# RE01_1500KB register map
Vendor: Renesas Electronics Corporation; Series: RE01_1500KB; File version: 1.20
CPU: CM0PLUS r0p1, little endian, MPU, no FPU, VTOR, 2 interrupt priority bits
Registers are 8-bit, read-write, reset 0x0 unless marked. A register's access mark holds for its fields unless they carry their own. Offsets are from the block's base; [hi:lo] are bit positions; {n}, {i} and the like mark numbered series; 'fields as' and 'values as' point back to an identical list; <NAME> marks a mode.

## SYSTEM — Energy Harvest Control Circuit
Base 0x4001E000
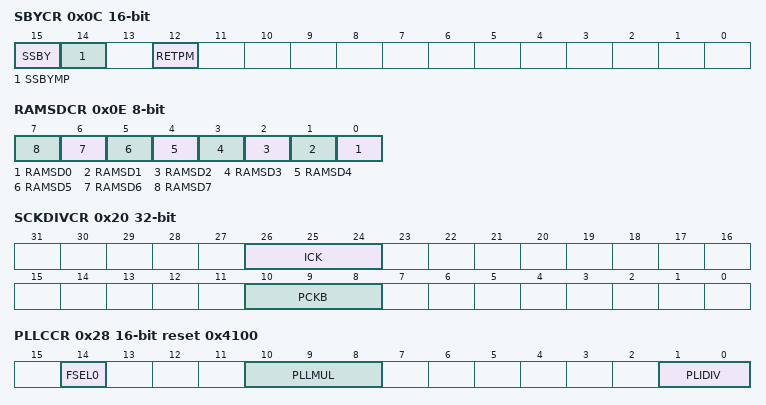
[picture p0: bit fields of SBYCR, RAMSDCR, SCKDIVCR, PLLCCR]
0x0C SBYCR 16-bit — Standby Control Register
  [15] SSBY — Software Standby
  [14] SSBYMP
  [12] RETPM
0x0E RAMSDCR
  [n] RAMSD{n} (n=0..7)
0x1C MSTPCRA 32-bit reset 0xFFBFFFFF — Module Stop Control Register A
  [22] MSTPA22 — Data Transfer Controller Module Stop
    0=Cancel the module-stop state; 1=Enter the module-stop state
0x20 SCKDIVCR 32-bit — System Clock Division Control Register
  [26:24] ICK — System Clock (ICLK)/Peripheral Module Clock A(PCLKA) Select
    0=/1; 1=/2; 2=/4; 3=/8; 4=/16; 5=/32; 6=/64; other=others (Setting prohibited)
  [10:8] PCKB — Peripheral Module Clock B (PCLKB) Select
    values as ICK
0x26 SCKSCR reset 0x1 — System Clock Source Control Register
  [2:0] CKSEL — Clock Source Select
    0=HOCO; 1=MOCO; 2=LOCO; 3=Main clock oscillator; 4=Sub-clock oscillator; 5=PLL; other=others (Setting prohibited)
0x28 PLLCCR 16-bit reset 0x4100 — PLL Clock Control Register
  [14] FSEL0
  [10:8] PLLMUL — PLL Frequency Multiplication Factor Select
    0=Setting prohibited; {v}=x{v+1} (v=1..7)
  [1:0] PLIDIV — PLL Input Frequency Division Ratio Select
    {v}=/{v+1} (v=0..3)
0x2A PLLCR reset 0x1 — PLL Control Register
  [0] PLLSTP — PLL Stop Control
    0=Operate the PLL; 1=Stop the PLL
0x32 MOSCCR reset 0x1 — Main Clock Oscillator Control Register
  [0] MOSTP — Main Clock Oscillator Stop
    0=Main clock oscillator is operating; 1=Main clock oscillator is stopped
0x36 HOCOCR (reset mask 0xFE) — High-Speed On-Chip Oscillator Control Register
  [0] HCSTP — HOCO Stop
    0=HOCO is operating; 1=HOCO is stopped
0x37 HOCOMCR (reset mask 0xFE) — High-Speed On-Chip Oscillator Mode Control Register
  [1:0] HCFRQ — HOCO Frequency Select
    0=24MHz; 1=32MHz; 2=48MHz; 3=64MHz
0x38 MOCOCR — Middle-Speed On-Chip Oscillator Control Register
  [0] MCSTP — MOCO Stop
    0=MOCO is operating; 1=MOCO is stopped
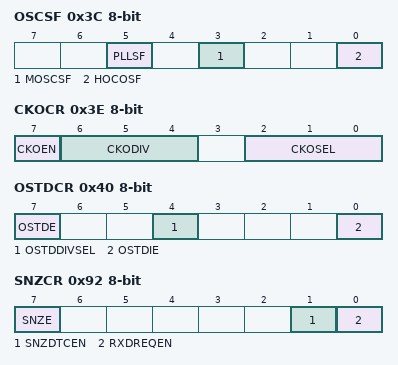
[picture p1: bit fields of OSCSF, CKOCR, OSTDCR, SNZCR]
0x3C OSCSF (reset mask 0xFE) — Oscillation Stabilization Flag Register
  [5] PLLSF ro — PLL Clock Oscillation Stabilization Flag
    0=The PLL clock is stopped or oscillation of the PLL clock has not yet become stable; 1=Oscillation of the PLL clock is stable so the clock is available for use as the system clock
  [3] MOSCSF ro — Main Clock Oscillation Stabilization Flag
    0=MOSTP = 1 (stopping the main clock oscillator) or oscillation of the main clock has not yet become stable; 1=Oscillation of the main clock is stable so the clock is available for use as the system clock
  [0] HOCOSF ro — HOCO Clock Oscillation Stabilization Flag
    0=The HOCO clock is stopped or oscillation of the HOCO clock has not yet become stable; 1=Oscillation of the HOCO clock is stable so the clock is available for use as the system clock
0x3D CKO32CR — 32kHz Clock Out Control Register
  [7] CKO32EN — 32kHz Clock Out enable
    0=Disable 32kHz clock out; 1=Enable 32kHz clock out
0x3E CKOCR — Clock Out Control Register
  [7] CKOEN — Clock Out enable
    0=Disable clock out; 1=Enable clock out
  [6:4] CKODIV — Clock Out input frequency Division Select
    0=/1; 1=/2; 2=/4; 3=/8; 4=/16; 5=/32; 6=/64; 7=/128
  [2:0] CKOSEL — Clock Out Source Select
    0=HOCO; 1=MOCO; 2=LOCO; 3=MOSC; 4=SOSC; 5=CCC_2K
0x40 OSTDCR — Oscillation Stop Detection Control Register
  [7] OSTDE — Oscillation Stop Detection Function Enable
    0=Oscillation stop detection function is disabled; 1=Oscillation stop detection function is enabled
  [4] OSTDDIVSEL
  [0] OSTDIE — Oscillation Stop Detection Interrupt Enable
    0=The oscillation stop detection interrupt is disabled. Oscillation stop detection is not notified to the POEG; 1=The oscillation stop detection interrupt is enabled. Oscillation stop detection is notified to the POEG
0x41 OSTDSR — Oscillation Stop Detection Status Register
  [0] OSTDF — Oscillation Stop Detection Flag
    0=The main clock oscillation stop has not been detected; 1=The main clock oscillation stop has been detected
0x92 SNZCR — Snooze Control Register
  [7] SNZE — Snooze Mode Enable
    0=Disable Snooze Mode; 1=Enable Snooze Mode
  [1] SNZDTCEN — DTC Enable in Snooze Mode
    0=Disable DTC operation; 1=Enable DTC operation
  [0] RXDREQEN — RXD0 Snooze Request Enable NOTE: Do not set to 1 other than in asynchronous mode.
    0=Ignore RXD0 falling edge in Standby mode; 1=Accept RXD0 falling edge in Standby mode as a request to transit to Snooze mode
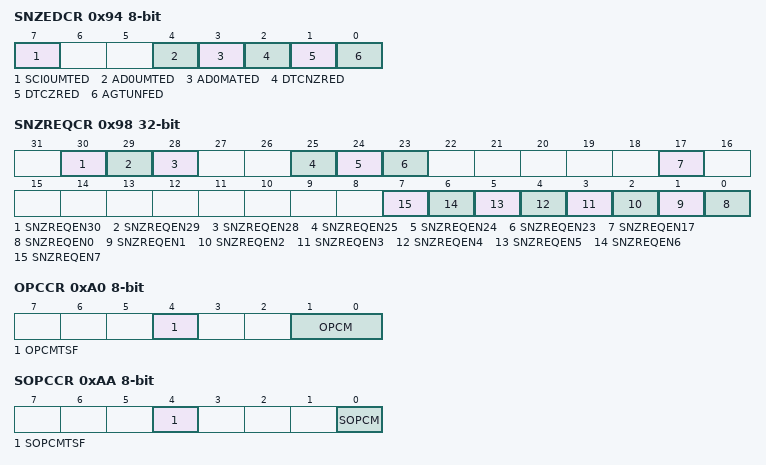
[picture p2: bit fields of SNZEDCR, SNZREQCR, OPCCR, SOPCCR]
0x94 SNZEDCR — Snooze End Control Register
  [all] fields
    0=Disable the Snooze End request; 1=Enable the Snooze End request
  [7] SCI0UMTED — SCI0 address unmatch Snooze End Enable
  [4] AD0UMTED — AD compare mismatch 0 Snooze End Enable
  [3] AD0MATED — AD compare match 0 Snooze End Enable
  [2] DTCNZRED — Not Last DTC transmission completion Snooze End Enable
  [1] DTCZRED — Last DTC transmission completion Snooze End Enable
  [0] AGTUNFED — AGT1 underflow Snooze End Enable
0x98 SNZREQCR 32-bit — Snooze Request Control Register
  [all] fields
    0=Disable snooze request; 1=Enable snooze request
  [30] SNZREQEN30 — Snooze Request Enable 30Enables the AGT0 compare match A Snooze request
  [29] SNZREQEN29 — Snooze Request Enable 29Enable AGT1 compare match A snooze request
  [28] SNZREQEN28 — Snooze Request Enable 28Enable AGT1 underflow snooze request
  [25] SNZREQEN25 — Snooze Request Enable 25Enable RTC period snooze request
  [24] SNZREQEN24 — Snooze Request Enable 24Enable RTC alarm snooze request
  [23] SNZREQEN23 — Snooze Request Enable 23Enable RTC alarm snooze request
  [17] SNZREQEN17 — Snooze Request Enable 17Enable KINT snooze request
  [n] SNZREQEN{n} (n=0..7) — Snooze Request Enable {n}Enable IRQ{n} pin snooze request
0xA0 OPCCR — Operating Power Control Register
  [4] OPCMTSF ro — Operating Power Control Mode Transition Status Flag
    0=Transition completed; 1=During transition
  [1:0] OPCM — Operating Power Control Mode Select
    0=High-speed mode; 3=Low-speed mode; other=others (Setting prohibited)
0xA2 MOSCWTCR reset 0x5 — Main Clock Oscillator Wait Control Register
  [3:0] MSTS — Main clock oscillator wait time setting
    0=Wait time= 3 cycles; 1=Wait time= 4 cycles; 2=Wait time= 8 cycles; 3=Wait time= 16 cycles; 4=Wait time= 32 cycles; 5=Wait time= 64 cycles (default); 6=Wait time= 128 cycles; 7=Wait time= 256 cycles; 8=Wait time= 512 cycles; 9=Wait time= 1024 cycles; other=others (Setting prohibited)
0xAA SOPCCR — Sub Operating Power Control Register
  [4] SOPCMTSF ro — Sub Operating Power Control Mode Transition Status Flag
    0=Transition completed; 1=During transition
  [0] SOPCM — Sub Operating Power Control Mode Select
    0=Other than Subosc-speed mode; 1=Subosc-speed mode
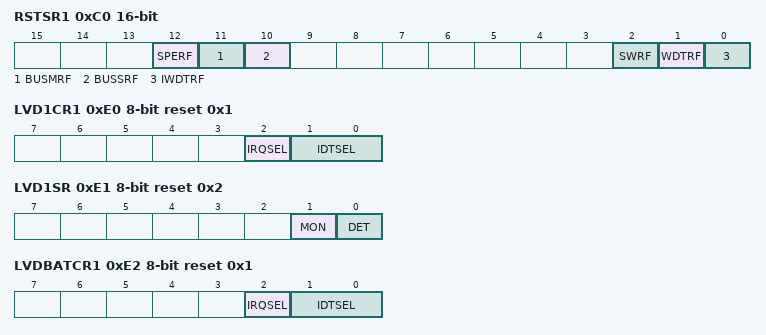
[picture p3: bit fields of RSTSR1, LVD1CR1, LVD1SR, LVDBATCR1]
0xC0 RSTSR1 16-bit (reset mask 0xE3F9) — Reset Status Register 1
  [12] SPERF — SP Error Reset Detect Flag
    0=SP error reset not detected; 1=SP error reset detected
  [11] BUSMRF — Bus Master MPU Error Reset Detect Flag
    0=Bus master MPU error reset not detected; 1=Bus master MPU error reset detected
  [10] BUSSRF — Bus Slave MPU Error Reset Detect Flag
    0=Bus slave MPU error reset not detected; 1=Bus slave MPU error reset detected
  [2] SWRF — Software Reset Detect Flag
    0=Software reset not detected; 1=Software reset detected
  [1] WDTRF — Watchdog Timer Reset Detect Flag
    0=Watchdog timer reset not detected; 1=Watchdog timer reset detected
  [0] IWDTRF — Independent Watchdog Timer Reset Detect Flag
    0=Independent watchdog timer reset not detected; 1=Independent watchdog timer reset detected
0xE0 LVD1CR1 reset 0x1 — Voltage Monitor 1 Circuit Control Register 1
  [2] IRQSEL — Voltage Monitor 1 Interrupt Type Select
    0=Non-maskable interrupt; 1=Maskable interrupt
  [1:0] IDTSEL — Voltage Monitor 1 Interrupt Generation Condition Select
    0=When VCC>=Vdet1 (rise) is detected; 1=When VCC<Vdet1 (drop) is detected; 2=When drop and rise are detected; 3=Settings prohibited
0xE1 LVD1SR reset 0x2 — Voltage Monitor 1 Circuit Status Register
  [1] MON ro — Voltage Monitor 1 Signal Monitor Flag
    0=VCC < Vdet1; 1=VCC >= Vdet1 or MON is disabled
  [0] DET — Voltage Monitor 1 Voltage Change Detection Flag
    0=Not detected; 1=Vdet1 passage detection
0xE2 LVDBATCR1 reset 0x1 — Voltage Monitor BAT Circuit Control Register 1
  [2] IRQSEL — Voltage Monitor BAT Interrupt Type Select
    0=Non-maskable interrupt; 1=Maskable interrupt
  [1:0] IDTSEL — Voltage Monitor BAT Interrupt Generation Condition Select
    0=When VBAT_EHC>=VdetBAT (rise) is detected; 1=When VBAT_EHC<VdetBAT (drop) is detected; 2=When drop and rise are detected; 3=Settings prohibited
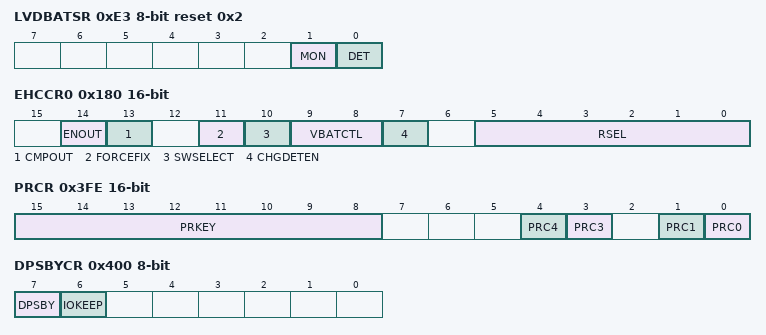
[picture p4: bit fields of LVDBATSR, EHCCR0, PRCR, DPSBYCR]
0xE3 LVDBATSR reset 0x2 — Voltage Monitor BAT Circuit Status Register
  [1] MON ro — Voltage Monitor BAT Signal Monitor Flag
    0=VBAT_EHC < VdetBAT; 1=VBAT_EHC >= VdetBAT or MON is disabled
  [0] DET — Voltage Monitor BAT Voltage Change Detection Flag
    0=Not detected; 1=VdetBAT passage detection
0x140 FSTPCR
  [0] FLFSTP
0x180 EHCCR0 16-bit (reset mask 0x9FFF) — Energy Harvest Control Register 0
  [14] ENOUT ro
  [13] CMPOUT ro
  [11] FORCEFIX wo
  [10] SWSELECT wo
  [9:8] VBATCTL wo
    0=00; 3=11; other=others (setting prohibited)
  [7] CHGDETEN wo
  [5:0] RSEL wo
    0=000000; 1=000001; 2=000010; 4=000100; 8=001000; 16=010000; 32=100000; other=others (: setting prohibited)
0x182 EHCCR1 — Energy Harvest Control Register 1
  [0] QUICKMODE
0x3FE PRCR 16-bit — Protect Register
  [15:8] PRKEY wo
  [4] PRC4
    0=Writes protected; 1=Writes not protected
  [3] PRC3 — Enables writing to the registers related to the LVD.
    0=Writes protected; 1=Writes not protected
  [1] PRC1
    0=Writes protected; 1=Writes not protected
  [0] PRC0
    0=Writes protected; 1=Writes not protected
0x400 DPSBYCR
  [7] DPSBY, [6] IOKEEP
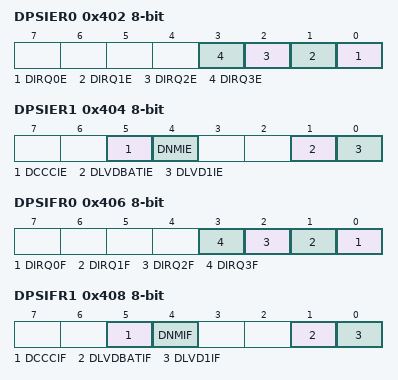
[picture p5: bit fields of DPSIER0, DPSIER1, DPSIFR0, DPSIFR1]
0x402 DPSIER0
  [n] DIRQ{n}E (n=0..3)
0x404 DPSIER1
  [5] DCCCIE, [4] DNMIE, [1] DLVDBATIE, [0] DLVD1IE
0x406 DPSIFR0
  [n] DIRQ{n}F (n=0..3)
0x408 DPSIFR1
  [5] DCCCIF, [4] DNMIF, [1] DLVDBATIF, [0] DLVD1IF
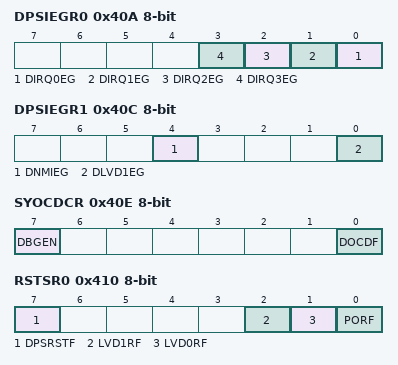
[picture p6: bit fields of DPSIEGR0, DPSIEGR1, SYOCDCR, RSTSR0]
0x40A DPSIEGR0
  [n] DIRQ{n}EG (n=0..3)
0x40C DPSIEGR1
  [4] DNMIEG, [0] DLVD1EG
0x40E SYOCDCR (reset mask 0xFE)
  [7] DBGEN, [0] DOCDF
0x410 RSTSR0 (reset mask 0x78) — Reset Status Register 0
  [7] DPSRSTF
  [2] LVD1RF
    0=Voltage monitor 1 reset not detected; 1=Voltage monitor 1 reset detected
  [1] LVD0RF
    0=Voltage monitor 0 reset not detected; 1=Voltage monitor 0 reset detected
  [0] PORF
    0=Power-on reset not detected; 1=Power-on reset detected
0x411 RSTSR2 (reset mask 0xFE) — Reset Status Register 2
  [0] CWSF — Cold/Warm Start Determination Flag
    0=Cold start; 1=Warm start
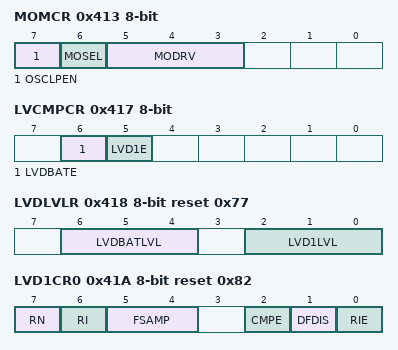
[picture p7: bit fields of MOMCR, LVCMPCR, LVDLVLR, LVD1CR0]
0x413 MOMCR — Main Clock Oscillator Mode Oscillation Control Register
  [7] OSCLPEN
  [6] MOSEL — Main Clock Oscillator Switching
    0=Resonator; 1=External clock input
  [5:3] MODRV
    0=000; 1=001; 2=010; 3=011; 4=100; 5=101; 6=110; 7=111
0x417 LVCMPCR — Voltage Monitor Circuit Control Register
  [6] LVDBATE — Voltage Detection BAT Enable
    0=Disable voltage detection BAT circuit; 1=Enable voltage detection BAT circuit
  [5] LVD1E — Voltage Detection 1 Enable
    0=Disable voltage detection 1 circuit; 1=Enable voltage detection 1 circuit
0x418 LVDLVLR reset 0x77 — Voltage Detection Level Select Register
  [6:4] LVDBATLVL — Voltage Detection BAT Level Select.(Standard voltage during fall in voltage)
    3=VdetBAT_5; 4=VdetBAT_7; 5=VdetBAT_9; 6=VdetBAT_B; 7=VdetBAT_D
  [2:0] LVD1LVL — Voltage Detection 1 Level Select.(Standard voltage during fall in voltage)
    0=Vdet1_0; 1=Vdet1_1; 2=Vdet1_3; 3=Vdet1_5; 4=Vdet1_7; 5=Vdet1_9; 6=Vdet1_B; 7=Vdet1_D
0x41A LVD1CR0 reset 0x82 — Voltage Monitor 1 Circuit Control Register 0
  [7] RN — Voltage Monitor 1 Reset Negate Select
    0=Negate after a stabilization time (tLVD1) when VCC > Vdet1 is detected; 1=Negate after a stabilization time (tLVD1) on assertion of the LVD1 reset
  [6] RI — Voltage Monitor 1 Circuit Mode Select
    0=Generate voltage monitor 1 interrupt on Vdet1 passage; 1=Enable voltage monitor 1 reset when the voltage falls to and below Vdet1
  [5:4] FSAMP
  [2] CMPE — Voltage Monitor 1 Circuit Comparison Result Output Enable
    0=Disable voltage monitor 1 circuit comparison result output; 1=Enable voltage monitor 1 circuit comparison result output
  [1] DFDIS
  [0] RIE — Voltage Monitor 1 Interrupt/Reset Enable
    0=Disable; 1=Enable
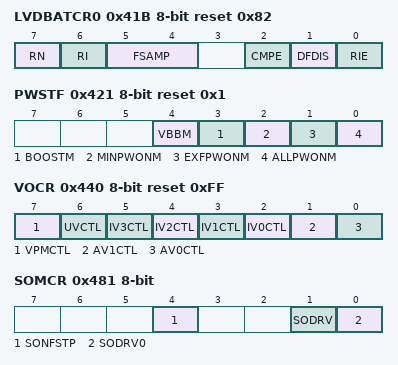
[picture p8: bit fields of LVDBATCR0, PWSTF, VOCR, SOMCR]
0x41B LVDBATCR0 reset 0x82 — Voltage Monitor BAT Circuit Control Register 0
  [7] RN — Voltage Monitor BAT Reset Negate Select
    0=Negate after a stabilization time (tLVDBAT) when VBAT_EHC > VdetBAT is detected; 1=Negate after a stabilization time (tLVDBAT) on assertion of the LVDBAT reset
  [6] RI — Voltage Monitor BAT Circuit Mode Select
    0=Generate voltage monitor BAT interrupt on VdetBAT passage; 1=Enable voltage monitor BAT reset when the voltage falls to and below VdetBAT
  [5:4] FSAMP
    0=00; 1=01; 2=10; 3=11
  [2] CMPE — Voltage Monitor BAT Circuit Comparison Result Output Enable
    0=Disable voltage monitor BAT circuit comparison result output; 1=Enable voltage monitor BAT circuit comparison result output
  [1] DFDIS
  [0] RIE — Voltage Monitor BAT Interrupt/Reset Enable
    0=Disable; 1=Enable
0x420 PWSTCR
  [2:0] PWST
0x421 PWSTF ro reset 0x1
  [4] VBBM, [3] BOOSTM, [2] MINPWONM, [1] EXFPWONM, [0] ALLPWONM
0x428 LDOCR
  [3] LDOCUT
0x440 VOCR reset 0xFF
  [7] VPMCTL — This bit is read as 1. The write value should be 1.
  [6] UVCTL
  [n+2] IV{n}CTL (n=0..3)
  [1] AV1CTL
  [0] AV0CTL
0x480 SOSCCR reset 0x1 — Sub-clock Oscillator Control Register
  [0] SOSTP — Sub-Clock Oscillator Stop
    0=Sub-clock oscillator is operating; 1=Sub-clock oscillator is stopped
0x481 SOMCR — Sub-clock Oscillator Mode Control Register
  [4] SONFSTP — Sub Clock Oscillator Drive Capability Switching
  [1] SODRV — Sub Clock Oscillator Drive Capability Switching
  [0] SODRV0
0x490 LOCOCR — Low-Speed On-Chip Oscillator Control Register
  [0] LCSTP — LOCO Stop
    0=LOCO is operating; 1=LOCO is stopped
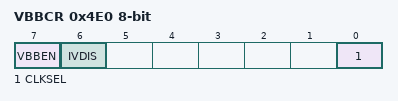
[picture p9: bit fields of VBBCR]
0x4E0 VBBCR (reset mask 0x7F) — VBB Control Register
  [7] VBBEN, [6] IVDIS, [0] CLKSEL
0x4E1 VBBST ro (reset mask 0xFE) — VBB Status Register
  [0] VBBSTUP
